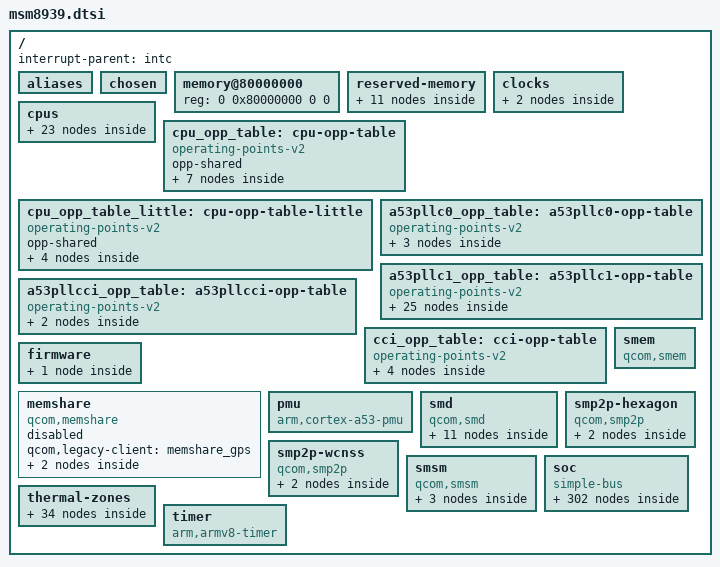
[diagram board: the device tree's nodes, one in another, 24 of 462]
// SPDX-License-Identifier: GPL-2.0-only
/*
 * Copyright (c) 2013-2015, The Linux Foundation. All rights reserved.
 */

#include <dt-bindings/arm/coresight-cti-dt.h>
#include <dt-bindings/clock/qcom,gcc-msm8939.h>
#include <dt-bindings/clock/qcom,rpmcc.h>
#include <dt-bindings/interconnect/qcom,msm8939.h>
#include <dt-bindings/interrupt-controller/arm-gic.h>
#include <dt-bindings/power/qcom-rpmpd.h>
#include <dt-bindings/reset/qcom,gcc-msm8939.h>
#include <dt-bindings/soc/qcom,apr.h>
#include <dt-bindings/soc/qcom,memshare.h>
#include <dt-bindings/thermal/thermal.h>

/ {
	interrupt-parent = <&intc>;

	#address-cells = <2>;
	#size-cells = <2>;

	aliases {
		sdhc1 = &sdhc_1; /* SDC1 eMMC slot */
		sdhc2 = &sdhc_2; /* SDC2 SD card slot */
	};

	chosen { };

	memory@80000000 {
		device_type = "memory";
		/* We expect the bootloader to fill in the reg */
		reg = <0 0x80000000 0 0>;
	};

	reserved-memory {
		#address-cells = <2>;
		#size-cells = <2>;
		ranges;

		tz-apps@86000000 {
			reg = <0x0 0x86000000 0x0 0x300000>;
			no-map;
		};

		smem_mem: smem_region@86300000 {
			reg = <0x0 0x86300000 0x0 0x100000>;
			no-map;
		};

		hypervisor@86400000 {
			reg = <0x0 0x86400000 0x0 0x100000>;
			no-map;
		};

		tz@86500000 {
			reg = <0x0 0x86500000 0x0 0x180000>;
			no-map;
		};

		reserved@86680000 {
			reg = <0x0 0x86680000 0x0 0x1000>;
			no-map;
		};

		rmtfs@86681000 {
			compatible = "qcom,rmtfs-mem";
			reg = <0x0 0x86681000 0x0 0x15f000>;
			no-map;

			qcom,client-id = <1>;
		};

		rfsa@867e0000 {
			reg = <0x0 0x867e0000 0x0 0x20000>;
			no-map;
		};

		mpss_mem: mpss@86800000 {
			reg = <0x0 0x86800000 0x0 0x5600000>;
			no-map;
		};

		wcnss_mem: wcnss@8be00000 {
			reg = <0x0 0x8be00000 0x0 0x600000>;
			no-map;
		};

		mba_mem: mba@8ea00000 {
			reg = <0x0 0x8ea00000 0x0 0x100000>;
			no-map;
		};

		venus_mem: venus@90000000 {
			reg = <0x0 0x90000000 0x0 0x600000>;
			no-map;
		};
	};

	clocks {
		xo_board: xo-board {
			compatible = "fixed-clock";
			#clock-cells = <0>;
			clock-frequency = <19200000>;
		};

		sleep_clk: sleep-clk {
			compatible = "fixed-clock";
			#clock-cells = <0>;
			clock-frequency = <32768>;
		};
	};

	cpus {
		#address-cells = <1>;
		#size-cells = <0>;

		cpu-map {
			cluster0 {	/* little */
				core0 {
					cpu = <&CPU4>;
				};
				core1 {
					cpu = <&CPU5>;
				};
				core2 {
					cpu = <&CPU6>;
				};
				core3 {
					cpu = <&CPU7>;
				};
			};

			cluster1 {	/* BIG */
				core0 {
					cpu = <&CPU0>;
				};
				core1 {
					cpu = <&CPU1>;
				};
				core2 {
					cpu = <&CPU2>;
				};
				core3 {
					cpu = <&CPU3>;
				};
			};
		};

		CPU0: cpu@100 {
			device_type = "cpu";
			compatible = "arm,cortex-a53";
			reg = <0x100>;
			next-level-cache = <&L2_1>;
			enable-method = "spin-table";
			clocks = <&apcs_mbox>;
			//operating-points-v2 = <&cpu_opp_table>;
			#cooling-cells = <2>;
			qcom,acc = <&cpu0_acc>;
			qcom,saw = <&cpu0_saw>;
			cpu-idle-states = <&CPU_SPC>;
		};

		CPU1: cpu@101 {
			device_type = "cpu";
			compatible = "arm,cortex-a53";
			reg = <0x101>;
			next-level-cache = <&L2_1>;
			enable-method = "spin-table";
			clocks = <&apcs_mbox>;
			//operating-points-v2 = <&cpu_opp_table>;
			#cooling-cells = <2>;
			qcom,acc = <&cpu1_acc>;
			qcom,saw = <&cpu1_saw>;
		};

		CPU2: cpu@102 {
			device_type = "cpu";
			compatible = "arm,cortex-a53";
			reg = <0x102>;
			next-level-cache = <&L2_1>;
			enable-method = "spin-table";
			clocks = <&apcs_mbox>;
			//operating-points-v2 = <&cpu_opp_table>;
			#cooling-cells = <2>;
			qcom,acc = <&cpu2_acc>;
			qcom,saw = <&cpu2_saw>;
		};

		CPU3: cpu@103 {
			device_type = "cpu";
			compatible = "arm,cortex-a53";
			reg = <0x103>;
			next-level-cache = <&L2_1>;
			enable-method = "spin-table";
			clocks = <&apcs_mbox>;
			//operating-points-v2 = <&cpu_opp_table>;
			#cooling-cells = <2>;
			qcom,acc = <&cpu3_acc>;
			qcom,saw = <&cpu3_saw>;
		};

		CPU4: cpu@0 {
			device_type = "cpu";
			compatible = "arm,cortex-a53";
			reg = <0x0>;
			next-level-cache = <&L2_0>;
			enable-method = "spin-table";
			clocks = <&apcs0>;
			//operating-points-v2 = <&cpu_opp_table_little>;
			#cooling-cells = <2>;
			qcom,acc = <&cpu4_acc>;
			qcom,saw = <&cpu4_saw>;
		};

		CPU5: cpu@1 {
			device_type = "cpu";
			compatible = "arm,cortex-a53";
			reg = <0x1>;
			next-level-cache = <&L2_0>;
			enable-method = "spin-table";
			clocks = <&apcs0>;
			//operating-points-v2 = <&cpu_opp_table_little>;
			#cooling-cells = <2>;
			qcom,acc = <&cpu5_acc>;
			qcom,saw = <&cpu5_saw>;
		};

		CPU6: cpu@2 {
			device_type = "cpu";
			compatible = "arm,cortex-a53";
			reg = <0x2>;
			next-level-cache = <&L2_0>;
			enable-method = "spin-table";
			clocks = <&apcs0>;
			//operating-points-v2 = <&cpu_opp_table_little>;
			#cooling-cells = <2>;
			qcom,acc = <&cpu6_acc>;
			qcom,saw = <&cpu6_saw>;
		};

		CPU7: cpu@3 {
			device_type = "cpu";
			compatible = "arm,cortex-a53";
			reg = <0x3>;
			next-level-cache = <&L2_0>;
			enable-method = "spin-table";
			clocks = <&apcs0>;
			//operating-points-v2 = <&cpu_opp_table_little>;
			#cooling-cells = <2>;
			qcom,acc = <&cpu7_acc>;
			qcom,saw = <&cpu7_saw>;
		};

		L2_0: l2-cache { /* little cluster */
			compatible = "cache";
			cache-level = <2>;
		};

		L2_1: l2-cache-1 { /* BIG cluster */
			compatible = "cache";
			cache-level = <2>;
		};

		idle-states {
			CPU_SPC: spc {
				compatible = "arm,idle-state";
				arm,psci-suspend-param = <0x40000002>;
				entry-latency-us = <130>;
				exit-latency-us = <150>;
				min-residency-us = <2000>;
				local-timer-stop;
			};
		};
	};

	cpu_opp_table: cpu-opp-table {
		compatible = "operating-points-v2";
		opp-shared;

		opp-200000000 {
			opp-hz = /bits/ 64 <200000000>;
		};
		opp-345600000 {
			opp-hz = /bits/ 64 <345600000>;
		};
		opp-400000000 {
			opp-hz = /bits/ 64 <400000000>;
		};
		opp-533330000 {
			opp-hz = /bits/ 64 <533330000>;
		};
		opp-800000000 {
			opp-hz = /bits/ 64 <800000000>;
		};
		opp-960000000 {
			opp-hz = /bits/ 64 <960000000>;
		};
		opp-1113600000 {
			opp-hz = /bits/ 64 <1113600000>;
		};
		/*
		opp-1344000000 {
			opp-hz = /bits/ 64 <1344000000>;
		};
		opp-1459200000 {
			opp-hz = /bits/ 64 <1459200000>;
		};
		opp-1497600000 {
			opp-hz = /bits/ 64 <1497600000>;
		};
		opp-1651200000 {
			opp-hz = /bits/ 64 <1651200000>;
		};
		*/
	};

	cpu_opp_table_little: cpu-opp-table-little {
		compatible = "operating-points-v2";
		opp-shared;

		opp-200000000 {
			opp-hz = /bits/ 64 <200000000>;
		};
		opp-249600000 {
			opp-hz = /bits/ 64 <249600000>;
		};
		opp-499200000 {
			opp-hz = /bits/ 64 <499200000>;
		};
		opp-800000000 {
			opp-hz = /bits/ 64 <800000000>;
		};
		/*
		opp-998400000 {
			opp-hz = /bits/ 64 <998400000>;
		};
		opp-1113600000 {
			opp-hz = /bits/ 64 <1113600000>;
		};
		*/
	};

	a53pllc0_opp_table: a53pllc0-opp-table {
		compatible = "operating-points-v2";

		opp-998400000 {
			opp-hz = /bits/ 64 <998400000>;
		};

		opp-1113600000 {
			opp-hz = /bits/ 64 <1113600000>;
		};

		opp-1209600000 {
			opp-hz = /bits/ 64 <1209600000>;
		};
	};

	a53pllc1_opp_table: a53pllc1-opp-table {
		compatible = "operating-points-v2";

		opp-652800000 {
			opp-hz = /bits/ 64 <652800000>;
		};

		opp-691200000 {
			opp-hz = /bits/ 64 <691200000>;
		};

		opp-729600000 {
			opp-hz = /bits/ 64 <729600000>;
		};

		opp-806400000 {
			opp-hz = /bits/ 64 <806400000>;
		};

		opp-844800000 {
			opp-hz = /bits/ 64 <844800000>;
		};

		opp-883200000 {
			opp-hz = /bits/ 64 <883200000>;
		};

		opp-960000000 {
			opp-hz = /bits/ 64 <960000000>;
		};

		opp-998400000 {
			opp-hz = /bits/ 64 <998400000>;
		};

		opp-1036800000 {
			opp-hz = /bits/ 64 <1036800000>;
		};

		opp-1113600000 {
			opp-hz = /bits/ 64 <1113600000>;
		};

		opp-1190400000 {
			opp-hz = /bits/ 64 <1190400000>;
		};

		opp-1209600000 {
			opp-hz = /bits/ 64 <1209600000>;
		};

		opp-1267200000 {
			opp-hz = /bits/ 64 <1267200000>;
		};

		opp-1344000000 {
			opp-hz = /bits/ 64 <1344000000>;
		};

		opp-1363200000 {
			opp-hz = /bits/ 64 <1363200000>;
		};

		opp-1420800000 {
			opp-hz = /bits/ 64 <1420800000>;
		};

		opp-1459200000 {
			opp-hz = /bits/ 64 <1459200000>;
		};

		opp-1497600000 {
			opp-hz = /bits/ 64 <1497600000>;
		};

		opp-1536000000 {
			opp-hz = /bits/ 64 <1536000000>;
		};

		opp-1574400000 {
			opp-hz = /bits/ 64 <1574400000>;
		};

		opp-1612800000 {
			opp-hz = /bits/ 64 <1612800000>;
		};

		opp-1632000000 {
			opp-hz = /bits/ 64 <1632000000>;
		};

		opp-1651200000 {
			opp-hz = /bits/ 64 <1651200000>;
		};

		opp-1689600000 {
			opp-hz = /bits/ 64 <1689600000>;
		};

		opp-1708800000 {
			opp-hz = /bits/ 64 <1708800000>;
		};
	};

	a53pllcci_opp_table: a53pllcci-opp-table {
		compatible = "operating-points-v2";

		opp-403200000 {
			opp-hz = /bits/ 64 <403200000>;
		};

		opp-595200000 {
			opp-hz = /bits/ 64 <595200000>;
		};
	};

	cci_opp_table: cci-opp-table {
		compatible = "operating-points-v2";

		opp-200000000 {
			opp-hz = /bits/ 64 <200000000>;
		};

		opp-297600000 {
			opp-hz = /bits/ 64 <297600000>;
		};

		opp-400000000 {
			opp-hz = /bits/ 64 <400000000>;
		};

		opp-595200000 {
			opp-hz = /bits/ 64 <595200000>;
		};

		/* Frequency mapping between cci and cluster/cpu */
		/*
		cpu-to-dev-map-0 =
			<  200000  200000 >,
			<  345600  200000 >,
			<  400000  200000 >,
			<  533330  297600 >,
			<  800000  297600 >,
			<  960000  297600 >,
			< 1113600  297000 >,
			< 1344000  595200 >,
			< 1459200  595200 >,
			< 1497600  595200 >,
			< 1651200  595200 >;
		cpu-to-dev-map-4 =
			<  200000 200000 >,
			<  249600 200000 >,
			<  499200 297600 >,
			<  800000 297600 >,
			<  998400 595200 >,
			< 1113600 595200 >;
		*/
	};

	firmware {
		scm: scm {
			compatible = "qcom,scm-msm8916", "qcom,scm";
			clocks = <&gcc GCC_CRYPTO_CLK>,
				 <&gcc GCC_CRYPTO_AXI_CLK>,
				 <&gcc GCC_CRYPTO_AHB_CLK>;
			clock-names = "core", "bus", "iface";
			#reset-cells = <1>;

			qcom,dload-mode = <&tcsr 0x6100>;
		};
	};

	memshare: memshare {
		compatible = "qcom,memshare";
		qcom,legacy-client = <&memshare_gps>;

		status = "disabled";

		#address-cells = <1>;
		#size-cells = <0>;

		mpss@0 {
			reg = <MEMSHARE_PROC_MPSS_V01>;
			qcom,qrtr-node = <0>;

			#address-cells = <1>;
			#size-cells = <0>;

			memshare_gps: gps@0 {
				reg = <0>;
			};
		};
	};

	pmu {
		compatible = "arm,cortex-a53-pmu";
		interrupts = <GIC_PPI 7 (GIC_CPU_MASK_SIMPLE(4) | IRQ_TYPE_LEVEL_HIGH)>;
	};

	smd {
		compatible = "qcom,smd";

		rpm {
			interrupts = <GIC_SPI 168 IRQ_TYPE_EDGE_RISING>;
			qcom,ipc = <&apcs 8 0>;
			qcom,smd-edge = <15>;

			rpm_requests: rpm-requests {
				compatible = "qcom,rpm-msm8936";
				qcom,smd-channels = "rpm_requests";

				rpmcc: clock-controller {
					compatible = "qcom,rpmcc-msm8936";
					#clock-cells = <1>;
				};

				rpmpd: power-controller {
					compatible = "qcom,msm8939-rpmpd";
					#power-domain-cells = <1>;
					operating-points-v2 = <&rpmpd_opp_table>;

					rpmpd_opp_table: opp-table {
						compatible = "operating-points-v2";

						rpmpd_opp_ret: opp1 {
							opp-level = <1>;
						};
						rpmpd_opp_svs_krait: opp2 {
							opp-level = <2>;
						};
						rpmpd_opp_svs_soc: opp3 {
							opp-level = <3>;
						};
						rpmpd_opp_nom: opp4 {
							opp-level = <4>;
						};
						rpmpd_opp_turbo: opp5 {
							opp-level = <5>;
						};
						rpmpd_opp_super_turbo: opp6 {
							opp-level = <6>;
						};
					};
				};
			};
		};
	};

	smem {
		compatible = "qcom,smem";

		memory-region = <&smem_mem>;
		qcom,rpm-msg-ram = <&rpm_msg_ram>;

		hwlocks = <&tcsr_mutex 3>;
	};

	smp2p-hexagon {
		compatible = "qcom,smp2p";
		qcom,smem = <435>, <428>;

		interrupts = <GIC_SPI 27 IRQ_TYPE_EDGE_RISING>;

		mboxes = <&apcs_mbox 14>;

		qcom,local-pid = <0>;
		qcom,remote-pid = <1>;

		hexagon_smp2p_out: master-kernel {
			qcom,entry-name = "master-kernel";

			#qcom,smem-state-cells = <1>;
		};

		hexagon_smp2p_in: slave-kernel {
			qcom,entry-name = "slave-kernel";

			interrupt-controller;
			#interrupt-cells = <2>;
		};
	};

	smp2p-wcnss {
		compatible = "qcom,smp2p";
		qcom,smem = <451>, <431>;

		interrupts = <GIC_SPI 143 IRQ_TYPE_EDGE_RISING>;

		mboxes = <&apcs_mbox 18>;

		qcom,local-pid = <0>;
		qcom,remote-pid = <4>;

		wcnss_smp2p_out: master-kernel {
			qcom,entry-name = "master-kernel";

			#qcom,smem-state-cells = <1>;
		};

		wcnss_smp2p_in: slave-kernel {
			qcom,entry-name = "slave-kernel";

			interrupt-controller;
			#interrupt-cells = <2>;
		};
	};

	smsm {
		compatible = "qcom,smsm";

		#address-cells = <1>;
		#size-cells = <0>;

		qcom,ipc-1 = <&apcs 8 13>;
		qcom,ipc-3 = <&apcs 8 19>;

		apps_smsm: apps@0 {
			reg = <0>;

			#qcom,smem-state-cells = <1>;
		};

		hexagon_smsm: hexagon@1 {
			reg = <1>;
			interrupts = <GIC_SPI 26 IRQ_TYPE_EDGE_RISING>;

			interrupt-controller;
			#interrupt-cells = <2>;
		};

		wcnss_smsm: wcnss@6 {
			reg = <6>;
			interrupts = <GIC_SPI 144 IRQ_TYPE_EDGE_RISING>;

			interrupt-controller;
			#interrupt-cells = <2>;
		};
	};

	soc: soc {
		#address-cells = <1>;
		#size-cells = <1>;
		ranges = <0 0 0 0xffffffff>;
		compatible = "simple-bus";

		rng@22000 {
			compatible = "qcom,prng";
			reg = <0x00022000 0x200>;
			clocks = <&gcc GCC_PRNG_AHB_CLK>;
			clock-names = "core";
		};

		restart@4ab000 {
			compatible = "qcom,pshold";
			reg = <0x004ab000 0x4>;
		};

		qfprom: qfprom@5c000 {
			compatible = "qcom,qfprom";
			reg = <0x0005c000 0x1000>;
			#address-cells = <1>;
			#size-cells = <1>;
			tsens_caldata: caldata@d0 {
				reg = <0xd0 0x8>;
			};
			tsens_calsel: calsel@ec {
				reg = <0xec 0x4>;
			};
		};

		rpm_msg_ram: memory@60000 {
			compatible = "qcom,rpm-msg-ram";
			reg = <0x00060000 0x8000>;
		};

		bimc: interconnect@400000 {
			compatible = "qcom,msm8939-bimc";
			reg = <0x00400000 0x62000>;
			#interconnect-cells = <1>;
			clock-names = "bus", "bus_a";
			clocks = <&rpmcc RPM_SMD_BIMC_CLK>,
				 <&rpmcc RPM_SMD_BIMC_A_CLK>;
		};

		tsens: thermal-sensor@4a9000 {
			compatible = "qcom,msm8939-tsens";
			reg = <0x004a9000 0x1000>, /* TM */
			      <0x004a8000 0x1000>; /* SROT */
			nvmem-cells = <&tsens_caldata>, <&tsens_calsel>;
			nvmem-cell-names = "calib", "calib_sel";
			#qcom,sensors = <10>;
			interrupts = <GIC_SPI 184 IRQ_TYPE_LEVEL_HIGH>;
			interrupt-names = "uplow";
			#thermal-sensor-cells = <1>;
		};

		pcnoc: interconnect@500000 {
			compatible = "qcom,msm8939-pcnoc";
			reg = <0x00500000 0x11000>;
			#interconnect-cells = <1>;
			clock-names = "bus", "bus_a";
			clocks = <&rpmcc RPM_SMD_PCNOC_CLK>,
				 <&rpmcc RPM_SMD_PCNOC_A_CLK>;
		};

		snoc: interconnect@580000 {
			compatible = "qcom,msm8939-snoc";
			reg = <0x00580000 0x14080>;
			clock-names = "bus", "bus_a";
			clocks = <&rpmcc RPM_SMD_SNOC_CLK>,
				 <&rpmcc RPM_SMD_SNOC_A_CLK>;
			#interconnect-cells = <1>;
			status = "okay";

			snoc_mm: interconnect@580000 {
				compatible = "qcom,msm8939-snoc-mm";
				clock-names = "bus", "bus_a";
				clocks = <&rpmcc RPM_SMD_SYSMMNOC_CLK>,
					 <&rpmcc RPM_SMD_SYSMMNOC_A_CLK>;
				#interconnect-cells = <1>;
				status = "okay";
			};

		};

		stm: stm@802000 {
			compatible = "arm,coresight-stm", "arm,primecell";
			reg = <0x00802000 0x1000>,
			      <0x09280000 0x180000>;
			reg-names = "stm-base", "stm-stimulus-base";

			clocks = <&rpmcc RPM_QDSS_CLK>, <&rpmcc RPM_QDSS_A_CLK>;
			clock-names = "apb_pclk", "atclk";

			status = "disabled";

			out-ports {
				port {
					stm_out: endpoint {
						remote-endpoint = <&funnel0_in7>;
					};
				};
			};
		};

		/* System CTIs */
		/* CTI 0 - TMC connections */
		cti0: cti@810000 {
			compatible = "arm,coresight-cti", "arm,primecell";
			reg = <0x00810000 0x1000>;

			clocks = <&rpmcc RPM_QDSS_CLK>;
			clock-names = "apb_pclk";

			status = "disabled";
		};

		/* CTI 1 - TPIU connections */
		cti1: cti@811000 {
			compatible = "arm,coresight-cti", "arm,primecell";
			reg = <0x00811000 0x1000>;

			clocks = <&rpmcc RPM_QDSS_CLK>;
			clock-names = "apb_pclk";

			status = "disabled";
		};

		/* CTIs 2-11 - no information - not instantiated */

		tpiu: tpiu@820000 {
			compatible = "arm,coresight-tpiu", "arm,primecell";
			reg = <0x00820000 0x1000>;

			clocks = <&rpmcc RPM_QDSS_CLK>, <&rpmcc RPM_QDSS_A_CLK>;
			clock-names = "apb_pclk", "atclk";

			status = "disabled";

			in-ports {
				port {
					tpiu_in: endpoint {
						remote-endpoint = <&replicator_out1>;
					};
				};
			};
		};

		funnel0: funnel@821000 {
			compatible = "arm,coresight-dynamic-funnel", "arm,primecell";
			reg = <0x00821000 0x1000>;

			clocks = <&rpmcc RPM_QDSS_CLK>, <&rpmcc RPM_QDSS_A_CLK>;
			clock-names = "apb_pclk", "atclk";

			status = "disabled";

			in-ports {
				#address-cells = <1>;
				#size-cells = <0>;

				/*
				 * Not described input ports:
				 * 0 - connected to Resource and Power Manger CPU ETM
				 * 1 - not-connected
				 * 2 - connected to Modem CPU ETM
				 * 3 - not-connected
				 * 5 - not-connected
				 * 6 - connected trought funnel to Wireless CPU ETM
				 * 7 - connected to STM component
				 */

				port@4 {
					reg = <4>;
					funnel0_in4: endpoint {
						remote-endpoint = <&funnel1_out>;
					};
				};

				port@7 {
					reg = <7>;
					funnel0_in7: endpoint {
						remote-endpoint = <&stm_out>;
					};
				};
			};

			out-ports {
				port {
					funnel0_out: endpoint {
						remote-endpoint = <&etf_in>;
					};
				};
			};
		};

		replicator: replicator@824000 {
			compatible = "arm,coresight-dynamic-replicator", "arm,primecell";
			reg = <0x00824000 0x1000>;

			clocks = <&rpmcc RPM_QDSS_CLK>, <&rpmcc RPM_QDSS_A_CLK>;
			clock-names = "apb_pclk", "atclk";

			status = "disabled";

			out-ports {
				#address-cells = <1>;
				#size-cells = <0>;

				port@0 {
					reg = <0>;
					replicator_out0: endpoint {
						remote-endpoint = <&etr_in>;
					};
				};
				port@1 {
					reg = <1>;
					replicator_out1: endpoint {
						remote-endpoint = <&tpiu_in>;
					};
				};
			};

			in-ports {
				port {
					replicator_in: endpoint {
						remote-endpoint = <&etf_out>;
					};
				};
			};
		};

		etf: etf@825000 {
			compatible = "arm,coresight-tmc", "arm,primecell";
			reg = <0x00825000 0x1000>;

			clocks = <&rpmcc RPM_QDSS_CLK>, <&rpmcc RPM_QDSS_A_CLK>;
			clock-names = "apb_pclk", "atclk";

			status = "disabled";

			in-ports {
				port {
					etf_in: endpoint {
						remote-endpoint = <&funnel0_out>;
					};
				};
			};

			out-ports {
				port {
					etf_out: endpoint {
						remote-endpoint = <&replicator_in>;
					};
				};
			};
		};

		etr: etr@826000 {
			compatible = "arm,coresight-tmc", "arm,primecell";
			reg = <0x00826000 0x1000>;

			clocks = <&rpmcc RPM_QDSS_CLK>, <&rpmcc RPM_QDSS_A_CLK>;
			clock-names = "apb_pclk", "atclk";

			status = "disabled";

			in-ports {
				port {
					etr_in: endpoint {
						remote-endpoint = <&replicator_out0>;
					};
				};
			};
		};

		funnel1: funnel@841000 {	/* APSS funnel only 4 inputs are used */
			compatible = "arm,coresight-dynamic-funnel", "arm,primecell";
			reg = <0x00841000 0x1000>;

			clocks = <&rpmcc RPM_QDSS_CLK>, <&rpmcc RPM_QDSS_A_CLK>;
			clock-names = "apb_pclk", "atclk";

			status = "disabled";

			in-ports {
				#address-cells = <1>;
				#size-cells = <0>;

				port@0 {
					reg = <0>;
					funnel1_in0: endpoint {
						remote-endpoint = <&etm0_out>;
					};
				};
				port@1 {
					reg = <1>;
					funnel1_in1: endpoint {
						remote-endpoint = <&etm1_out>;
					};
				};
				port@2 {
					reg = <2>;
					funnel1_in2: endpoint {
						remote-endpoint = <&etm2_out>;
					};
				};
				port@3 {
					reg = <3>;
					funnel1_in3: endpoint {
						remote-endpoint = <&etm3_out>;
					};
				};
			};

			out-ports {
				port {
					funnel1_out: endpoint {
						remote-endpoint = <&funnel0_in4>;
					};
				};
			};
		};

		debug0: debug@850000 {
			compatible = "arm,coresight-cpu-debug", "arm,primecell";
			reg = <0x00850000 0x1000>;
			clocks = <&rpmcc RPM_QDSS_CLK>;
			clock-names = "apb_pclk";
			cpu = <&CPU0>;
			status = "disabled";
		};

		debug1: debug@852000 {
			compatible = "arm,coresight-cpu-debug", "arm,primecell";
			reg = <0x00852000 0x1000>;
			clocks = <&rpmcc RPM_QDSS_CLK>;
			clock-names = "apb_pclk";
			cpu = <&CPU1>;
			status = "disabled";
		};

		debug2: debug@854000 {
			compatible = "arm,coresight-cpu-debug", "arm,primecell";
			reg = <0x00854000 0x1000>;
			clocks = <&rpmcc RPM_QDSS_CLK>;
			clock-names = "apb_pclk";
			cpu = <&CPU2>;
			status = "disabled";
		};

		debug3: debug@856000 {
			compatible = "arm,coresight-cpu-debug", "arm,primecell";
			reg = <0x00856000 0x1000>;
			clocks = <&rpmcc RPM_QDSS_CLK>;
			clock-names = "apb_pclk";
			cpu = <&CPU3>;
			status = "disabled";
		};

		/* Core CTIs; CTIs 12-15 */
		/* CTI - CPU-0 */
		cti12: cti@858000 {
			compatible = "arm,coresight-cti-v8-arch", "arm,coresight-cti",
				     "arm,primecell";
			reg = <0x00858000 0x1000>;

			clocks = <&rpmcc RPM_QDSS_CLK>;
			clock-names = "apb_pclk";

			cpu = <&CPU0>;
			arm,cs-dev-assoc = <&etm0>;

			status = "disabled";
		};

		/* CTI - CPU-1 */
		cti13: cti@859000 {
			compatible = "arm,coresight-cti-v8-arch", "arm,coresight-cti",
				     "arm,primecell";
			reg = <0x00859000 0x1000>;

			clocks = <&rpmcc RPM_QDSS_CLK>;
			clock-names = "apb_pclk";

			cpu = <&CPU1>;
			arm,cs-dev-assoc = <&etm1>;

			status = "disabled";
		};

		/* CTI - CPU-2 */
		cti14: cti@85a000 {
			compatible = "arm,coresight-cti-v8-arch", "arm,coresight-cti",
				     "arm,primecell";
			reg = <0x0085a000 0x1000>;

			clocks = <&rpmcc RPM_QDSS_CLK>;
			clock-names = "apb_pclk";

			cpu = <&CPU2>;
			arm,cs-dev-assoc = <&etm2>;

			status = "disabled";
		};

		/* CTI - CPU-3 */
		cti15: cti@85b000 {
			compatible = "arm,coresight-cti-v8-arch", "arm,coresight-cti",
				     "arm,primecell";
			reg = <0x0085b000 0x1000>;

			clocks = <&rpmcc RPM_QDSS_CLK>;
			clock-names = "apb_pclk";

			cpu = <&CPU3>;
			arm,cs-dev-assoc = <&etm3>;

			status = "disabled";
		};

		etm0: etm@85c000 {
			compatible = "arm,coresight-etm4x", "arm,primecell";
			reg = <0x0085c000 0x1000>;

			clocks = <&rpmcc RPM_QDSS_CLK>, <&rpmcc RPM_QDSS_A_CLK>;
			clock-names = "apb_pclk", "atclk";
			arm,coresight-loses-context-with-cpu;

			cpu = <&CPU0>;

			status = "disabled";

			out-ports {
				port {
					etm0_out: endpoint {
						remote-endpoint = <&funnel1_in0>;
					};
				};
			};
		};

		etm1: etm@85d000 {
			compatible = "arm,coresight-etm4x", "arm,primecell";
			reg = <0x0085d000 0x1000>;

			clocks = <&rpmcc RPM_QDSS_CLK>, <&rpmcc RPM_QDSS_A_CLK>;
			clock-names = "apb_pclk", "atclk";
			arm,coresight-loses-context-with-cpu;

			cpu = <&CPU1>;

			status = "disabled";

			out-ports {
				port {
					etm1_out: endpoint {
						remote-endpoint = <&funnel1_in1>;
					};
				};
			};
		};

		etm2: etm@85e000 {
			compatible = "arm,coresight-etm4x", "arm,primecell";
			reg = <0x0085e000 0x1000>;

			clocks = <&rpmcc RPM_QDSS_CLK>, <&rpmcc RPM_QDSS_A_CLK>;
			clock-names = "apb_pclk", "atclk";
			arm,coresight-loses-context-with-cpu;

			cpu = <&CPU2>;

			status = "disabled";

			out-ports {
				port {
					etm2_out: endpoint {
						remote-endpoint = <&funnel1_in2>;
					};
				};
			};
		};

		etm3: etm@85f000 {
			compatible = "arm,coresight-etm4x", "arm,primecell";
			reg = <0x0085f000 0x1000>;

			clocks = <&rpmcc RPM_QDSS_CLK>, <&rpmcc RPM_QDSS_A_CLK>;
			clock-names = "apb_pclk", "atclk";
			arm,coresight-loses-context-with-cpu;

			cpu = <&CPU3>;

			status = "disabled";

			out-ports {
				port {
					etm3_out: endpoint {
						remote-endpoint = <&funnel1_in3>;
					};
				};
			};
		};

		msmgpio: pinctrl@1000000 {
			compatible = "qcom,msm8916-pinctrl";
			reg = <0x01000000 0x300000>;
			interrupts = <GIC_SPI 208 IRQ_TYPE_LEVEL_HIGH>;
			gpio-controller;
			gpio-ranges = <&msmgpio 0 0 122>;
			#gpio-cells = <2>;
			interrupt-controller;
			#interrupt-cells = <2>;

			blsp1_uart1_default: blsp1-uart1-default {
				pins = "gpio0", "gpio1", "gpio2", "gpio3";
				function = "blsp_uart1";

				drive-strength = <16>;
				bias-disable;
			};

			blsp1_uart1_sleep: blsp1-uart1-sleep {
				pins = "gpio0", "gpio1", "gpio2", "gpio3";
				function = "gpio";

				drive-strength = <2>;
				bias-pull-down;
			};

			blsp1_uart2_default: blsp1-uart2-default {
				pins = "gpio4", "gpio5";
				function = "blsp_uart2";

				drive-strength = <16>;
				bias-disable;
			};

			blsp1_uart2_sleep: blsp1-uart2-sleep {
				pins = "gpio4", "gpio5";
				function = "gpio";

				drive-strength = <2>;
				bias-pull-down;
			};

			camera_front_default: camera-front-default {
				pwdn {
					pins = "gpio33";
					function = "gpio";

					drive-strength = <16>;
					bias-disable;
				};
				rst {
					pins = "gpio28";
					function = "gpio";

					drive-strength = <16>;
					bias-disable;
				};
				mclk1 {
					pins = "gpio27";
					function = "cam_mclk1";

					drive-strength = <16>;
					bias-disable;
				};
			};

			camera_rear_default: camera-rear-default {
				pwdn {
					pins = "gpio34";
					function = "gpio";

					drive-strength = <16>;
					bias-disable;
				};
				rst {
					pins = "gpio35";
					function = "gpio";

					drive-strength = <16>;
					bias-disable;
				};
				mclk0 {
					pins = "gpio26";
					function = "cam_mclk0";

					drive-strength = <16>;
					bias-disable;
				};
			};

			cci0_default: cci0-default {
				pins = "gpio29", "gpio30";
				function = "cci_i2c";

				drive-strength = <16>;
				bias-disable;
			};

			cdc-pdm-lines {
				cdc_pdm_lines_act: pdm-lines-on {
					pins = "gpio63", "gpio64", "gpio65", "gpio66",
					       "gpio67", "gpio68";
					function = "cdc_pdm0";

					drive-strength = <8>;
					bias-disable;
				};
				cdc_pdm_lines_sus: pdm-lines-off {
					pins = "gpio63", "gpio64", "gpio65", "gpio66",
					       "gpio67", "gpio68";
					function = "cdc_pdm0";

					drive-strength = <2>;
					bias-pull-down;
				};
			};

			cdc-dmic-lines {
				cdc_dmic_lines_act: dmic-lines-on {
					clk {
						pins = "gpio0";
						function = "dmic0_clk";

						drive-strength = <8>;
					};
					data {
						pins = "gpio1";
						function = "dmic0_data";

						drive-strength = <8>;
					};
				};
				cdc_dmic_lines_sus: dmic-lines-off {
					clk {
						pins = "gpio0";
						function = "dmic0_clk";

						drive-strength = <2>;
						bias-disable;
					};
					data {
						pins = "gpio1";
						function = "dmic0_data";

						drive-strength = <2>;
						bias-disable;
					};
				};
			};

			ext-mclk-tlmm-lines {
				ext_mclk_tlmm_lines_act: mclk-lines-on {
					pins = "gpio116";
					function = "pri_mi2s";

					drive-strength = <8>;
					bias-disable;
				};
				ext_mclk_tlmm_lines_sus: mclk-lines-off {
					pins = "gpio116";
					function = "pri_mi2s";

					drive-strength = <2>;
					bias-disable;
				};
			};

			ext-pri-tlmm-lines {
				ext_pri_tlmm_lines_act: ext-pa-on {
					pins = "gpio113", "gpio114", "gpio115", "gpio116";
					function = "pri_mi2s";

					drive-strength = <8>;
					bias-disable;
				};
				ext_pri_tlmm_lines_sus: ext-pa-off {
					pins = "gpio113", "gpio114", "gpio115", "gpio116";
					function = "pri_mi2s";

					drive-strength = <2>;
					bias-disable;
				};
			};

			ext-pri-ws-line {
				ext_pri_ws_act: ext-pa-on {
					pins = "gpio110";
					function = "pri_mi2s_ws";

					drive-strength = <8>;
					bias-disable;
				};
				ext_pri_ws_sus: ext-pa-off {
					pins = "gpio110";
					function = "pri_mi2s_ws";

					drive-strength = <2>;
					bias-disable;
				};
			};

			/* secondary Mi2S */
			ext-sec-tlmm-lines {
				ext_sec_tlmm_lines_act: tlmm-lines-on {
					pins = "gpio112", "gpio117", "gpio118", "gpio119";
					function = "sec_mi2s";

					drive-strength = <8>;
					bias-disable;
				};
				ext_sec_tlmm_lines_sus: tlmm-lines-off {
					pins = "gpio112", "gpio117", "gpio118", "gpio119";
					function = "sec_mi2s";

					drive-strength = <2>;
					bias-disable;
				};
			};

			i2c1_default: i2c1-default {
				pins = "gpio2", "gpio3";
				function = "blsp_i2c1";

				drive-strength = <2>;
				bias-disable;
			};

			i2c1_sleep: i2c1-sleep {
				pins = "gpio2", "gpio3";
				function = "gpio";

				drive-strength = <2>;
				bias-disable;
			};

			i2c2_default: i2c2-default {
				pins = "gpio6", "gpio7";
				function = "blsp_i2c2";

				drive-strength = <2>;
				bias-disable;
			};

			i2c2_sleep: i2c2-sleep {
				pins = "gpio6", "gpio7";
				function = "gpio";

				drive-strength = <2>;
				bias-disable;
			};

			i2c3_default: i2c3-default {
				pins = "gpio10", "gpio11";
				function = "blsp_i2c3";

				drive-strength = <2>;
				bias-disable;
			};

			i2c3_sleep: i2c3-sleep {
				pins = "gpio10", "gpio11";
				function = "gpio";

				drive-strength = <2>;
				bias-disable;
			};

			i2c4_default: i2c4-default {
				pins = "gpio14", "gpio15";
				function = "blsp_i2c4";

				drive-strength = <2>;
				bias-disable;
			};

			i2c4_sleep: i2c4-sleep {
				pins = "gpio14", "gpio15";
				function = "gpio";

				drive-strength = <2>;
				bias-disable;
			};

			i2c5_default: i2c5-default {
				pins = "gpio18", "gpio19";
				function = "blsp_i2c5";

				drive-strength = <2>;
				bias-disable;
			};

			i2c5_sleep: i2c5-sleep {
				pins = "gpio18", "gpio19";
				function = "gpio";

				drive-strength = <2>;
				bias-disable;
			};

			i2c6_default: i2c6-default {
				pins = "gpio22", "gpio23";
				function = "blsp_i2c6";

				drive-strength = <2>;
				bias-disable;
			};

			i2c6_sleep: i2c6-sleep {
				pins = "gpio22", "gpio23";
				function = "gpio";

				drive-strength = <2>;
				bias-disable;
			};

			pmx-sdc1-clk {
				sdc1_clk_on: clk-on {
					pins = "sdc1_clk";

					bias-disable;
					drive-strength = <16>;
				};
				sdc1_clk_off: clk-off {
					pins = "sdc1_clk";

					bias-disable;
					drive-strength = <2>;
				};
			};

			pmx-sdc1-cmd {
				sdc1_cmd_on: cmd-on {
					pins = "sdc1_cmd";

					bias-pull-up;
					drive-strength = <10>;
				};
				sdc1_cmd_off: cmd-off {
					pins = "sdc1_cmd";

					bias-pull-up;
					drive-strength = <2>;
				};
			};

			pmx-sdc1-data {
				sdc1_data_on: data-on {
					pins = "sdc1_data";

					bias-pull-up;
					drive-strength = <10>;
				};
				sdc1_data_off: data-off {
					pins = "sdc1_data";

					bias-pull-up;
					drive-strength = <2>;
				};
			};

			pmx-sdc2-clk {
				sdc2_clk_on: clk-on {
					pins = "sdc2_clk";

					bias-disable;
					drive-strength = <16>;
				};
				sdc2_clk_off: clk-off {
					pins = "sdc2_clk";

					bias-disable;
					drive-strength = <2>;
				};
			};

			pmx-sdc2-cmd {
				sdc2_cmd_on: cmd-on {
					pins = "sdc2_cmd";

					bias-pull-up;
					drive-strength = <10>;
				};
				sdc2_cmd_off: cmd-off {
					pins = "sdc2_cmd";

					bias-pull-up;
					drive-strength = <2>;
				};
			};

			pmx-sdc2-data {
				sdc2_data_on: data-on {
					pins = "sdc2_data";

					bias-pull-up;
					drive-strength = <10>;
				};
				sdc2_data_off: data-off {
					pins = "sdc2_data";

					bias-pull-up;
					drive-strength = <2>;
				};
			};

			pmx-sdc2-cd-pin {
				sdc2_cd_on: cd-on {
					pins = "gpio38";
					function = "gpio";

					drive-strength = <2>;
					bias-pull-up;
				};
				sdc2_cd_off: cd-off {
					pins = "gpio38";
					function = "gpio";

					drive-strength = <2>;
					bias-disable;
				};
			};

			spi1_default: spi1-default {
				pins = "gpio0", "gpio1", "gpio3";
				function = "blsp_spi1";

				drive-strength = <12>;
				bias-disable;

				cs {
					pins = "gpio2";
					function = "gpio";

					drive-strength = <16>;
					bias-disable;
					output-high;
				};
			};

			spi1_sleep: spi1-sleep {
				pins = "gpio0", "gpio1", "gpio2", "gpio3";
				function = "gpio";

				drive-strength = <2>;
				bias-pull-down;
			};

			spi2_default: spi2-default {
				pins = "gpio4", "gpio5", "gpio7";
				function = "blsp_spi2";

				drive-strength = <12>;
				bias-disable;

				cs {
					pins = "gpio6";
					function = "gpio";

					drive-strength = <16>;
					bias-disable;
					output-high;
				};
			};

			spi2_sleep: spi2-sleep {
				pins = "gpio4", "gpio5", "gpio6", "gpio7";
				function = "gpio";

				drive-strength = <2>;
				bias-pull-down;
			};

			spi3_default: spi3-default {
				pins = "gpio8", "gpio9", "gpio11";
				function = "blsp_spi3";

				drive-strength = <12>;
				bias-disable;

				cs {
					pins = "gpio10";
					function = "gpio";

					drive-strength = <16>;
					bias-disable;
					output-high;
				};
			};

			spi3_sleep: spi3-sleep {
				pins = "gpio8", "gpio9", "gpio10", "gpio11";
				function = "gpio";

				drive-strength = <2>;
				bias-pull-down;
			};

			spi4_default: spi4-default {
				pins = "gpio12", "gpio13", "gpio15";
				function = "blsp_spi4";

				drive-strength = <12>;
				bias-disable;

				cs {
					pins = "gpio14";
					function = "gpio";

					drive-strength = <16>;
					bias-disable;
					output-high;
				};
			};

			spi4_sleep: spi4-sleep {
				pins = "gpio12", "gpio13", "gpio14", "gpio15";
				function = "gpio";

				drive-strength = <2>;
				bias-pull-down;
			};

			spi5_default: spi5-default {
				pins = "gpio16", "gpio17", "gpio19";
				function = "blsp_spi5";

				drive-strength = <12>;
				bias-disable;

				cs {
					pins = "gpio18";
					function = "gpio";

					drive-strength = <16>;
					bias-disable;
					output-high;
				};
			};

			spi5_sleep: spi5-sleep {
				pins = "gpio16", "gpio17", "gpio18", "gpio19";
				function = "gpio";

				drive-strength = <2>;
				bias-pull-down;
			};

			spi6_default: spi6-default {
				pins = "gpio20", "gpio21", "gpio23";
				function = "blsp_spi6";

				drive-strength = <12>;
				bias-disable;

				cs {
					pins = "gpio22";
					function = "gpio";

					drive-strength = <16>;
					bias-disable;
					output-high;
				};
			};

			spi6_sleep: spi6-sleep {
				pins = "gpio20", "gpio21", "gpio22", "gpio23";
				function = "gpio";

				drive-strength = <2>;
				bias-pull-down;
			};

			wcnss_pin_a: wcnss-active {
				pins = "gpio40", "gpio41", "gpio42", "gpio43", "gpio44";
				function = "wcss_wlan";

				drive-strength = <6>;
				bias-pull-up;
			};

		};

		gcc: clock-controller@1800000 {
			compatible = "qcom,gcc-msm8939";
			#clock-cells = <1>;
			#reset-cells = <1>;
			#power-domain-cells = <1>;
			reg = <0x01800000 0x80000>;
			clock-names = "xo",
				      "sleep_clk";
			clocks = <&xo_board>,
				 <&sleep_clk>;
		};

		tcsr_mutex: hwlock@1905000 {
			compatible = "qcom,tcsr-mutex";
			reg = <0x01905000 0x20000>;
			#hwlock-cells = <1>;
		};

		tcsr: syscon@1937000 {
			compatible = "qcom,tcsr-msm8916", "syscon";
			reg = <0x01937000 0x30000>;
		};

		mdss: mdss@1a00000 {
			compatible = "qcom,mdss";
			reg = <0x01a00000 0x1000>,
			      <0x01ac8000 0x3000>;
			reg-names = "mdss_phys", "vbif_phys";

			interrupts = <GIC_SPI 72 IRQ_TYPE_LEVEL_HIGH>;
			interrupt-controller;

			clocks = <&gcc GCC_MDSS_AHB_CLK>,
				 <&gcc GCC_MDSS_AXI_CLK>,
				 <&gcc GCC_MDSS_VSYNC_CLK>;
			clock-names = "iface",
				      "bus",
				      "vsync";

			power-domains = <&gcc MDSS_GDSC>;

			#address-cells = <1>;
			#size-cells = <1>;
			#interrupt-cells = <1>;
			ranges;

			mdss_mdp: mdp@1a01000 {
				compatible = "qcom,mdp5";
				reg = <0x01a01000 0x89000>;
				reg-names = "mdp_phys";

				interrupt-parent = <&mdss>;
				interrupts = <0>;

				clocks = <&gcc GCC_MDSS_AHB_CLK>,
					 <&gcc GCC_MDSS_AXI_CLK>,
					 <&gcc GCC_MDSS_MDP_CLK>,
					 <&gcc GCC_MDSS_VSYNC_CLK>,
					 <&gcc GCC_MDP_TBU_CLK>,
					 <&gcc GCC_MDP_RT_TBU_CLK>;
				clock-names = "iface",
					      "bus",
					      "core",
					      "vsync",
					      "tbu",
					      "tbu_rt";

				iommus = <&apps_iommu 4>;

				interconnects = <&snoc_mm MASTER_MDP_PORT0 &bimc SLAVE_EBI_CH0>,
						<&snoc_mm MASTER_MDP_PORT1 &bimc SLAVE_EBI_CH0>;
				interconnect-names = "mdp0-mem", "mdp1-mem";

				ports {
					#address-cells = <1>;
					#size-cells = <0>;

					port@0 {
						reg = <0>;
						mdp5_intf1_out: endpoint {
							remote-endpoint = <&dsi0_in>;
						};
					};

					port@1 {
						reg = <1>;
						mdp5_intf2_out: endpoint {
							remote-endpoint = <&dsi1_in>;
						};
					};
				};
			};


			mdss_dsi0: dsi@1a98000 {
				compatible = "qcom,mdss-dsi-ctrl";
				reg = <0x01a98000 0x25c>;
				reg-names = "dsi_ctrl";

				interrupt-parent = <&mdss>;
				interrupts = <4>;

				clocks = <&gcc GCC_MDSS_MDP_CLK>,
					 <&gcc GCC_MDSS_AHB_CLK>,
					 <&gcc GCC_MDSS_AXI_CLK>,
					 <&gcc GCC_MDSS_BYTE0_CLK>,
					 <&gcc GCC_MDSS_PCLK0_CLK>,
					 <&gcc GCC_MDSS_ESC0_CLK>;
				clock-names = "mdp_core",
					      "iface",
					      "bus",
					      "byte",
					      "pixel",
					      "core";
				assigned-clocks = <&gcc BYTE0_CLK_SRC>,
						  <&gcc PCLK0_CLK_SRC>;
				assigned-clock-parents = <&mdss_dsi0_phy 0>,
							 <&mdss_dsi0_phy 1>;

				phys = <&mdss_dsi0_phy>;
				phy-names = "dsi-phy";
				status = "disabled";

				#address-cells = <1>;
				#size-cells = <0>;

				ports {
					#address-cells = <1>;
					#size-cells = <0>;

					port@0 {
						reg = <0>;
						dsi0_in: endpoint {
							remote-endpoint = <&mdp5_intf1_out>;
						};
					};

					port@1 {
						reg = <1>;
						dsi0_out: endpoint {
						};
					};
				};
			};

			mdss_dsi0_phy: dsi-phy@1a98300 {
				compatible = "qcom,dsi-phy-28nm-lp";
				reg = <0x01a98300 0xd4>,
				      <0x01a98500 0x280>,
				      <0x01a98780 0x30>;
				reg-names = "dsi_pll",
					    "dsi_phy",
					    "dsi_phy_regulator";

				clocks = <&gcc GCC_MDSS_AHB_CLK>,
					 <&xo_board>;
				clock-names = "iface", "ref";

				#clock-cells = <1>;
				#phy-cells = <0>;

				qcom,dsi-phy-regulator-ldo-mode;
				status = "disabled";
			};

			mdss_dsi1: dsi@1aa0000 {
				compatible = "qcom,mdss-dsi-ctrl";
				reg = <0x01aa0000 0x25c>;
				reg-names = "dsi_ctrl";

				interrupt-parent = <&mdss>;
				interrupts = <5>;

				clocks = <&gcc GCC_MDSS_MDP_CLK>,
					 <&gcc GCC_MDSS_AHB_CLK>,
					 <&gcc GCC_MDSS_AXI_CLK>,
					 <&gcc GCC_MDSS_BYTE1_CLK>,
					 <&gcc GCC_MDSS_PCLK1_CLK>,
					 <&gcc GCC_MDSS_ESC1_CLK>;
				clock-names = "mdp_core",
					      "iface",
					      "bus",
					      "byte",
					      "pixel",
					      "core";

				assigned-clocks = <&gcc BYTE1_CLK_SRC>,
						  <&gcc PCLK1_CLK_SRC>;
				assigned-clock-parents = <&mdss_dsi1_phy 0>,
							 <&mdss_dsi1_phy 1>;
				phys = <&mdss_dsi1_phy>;
				phy-names = "dsi-phy";
				status = "disabled";

				ports {
					#address-cells = <1>;
					#size-cells = <0>;

					port@0 {
						reg = <0>;
						dsi1_in: endpoint {
							remote-endpoint = <&mdp5_intf2_out>;
						};
					};

					port@1 {
						reg = <1>;
						dsi1_out: endpoint {
						};
					};
				};
			};

			mdss_dsi1_phy: dsi-phy@1aa0300 {
				compatible = "qcom,dsi-phy-28nm-lp";
				reg = <0x01aa0300 0xd4>,
				      <0x01aa0500 0x280>,
				      <0x01aa0780 0x30>;
				reg-names = "dsi_pll",
					    "dsi_phy",
					    "dsi_phy_regulator";

				clocks = <&gcc GCC_MDSS_AHB_CLK>,
					 <&xo_board>;
				clock-names = "iface", "ref";

				#clock-cells = <1>;
				#phy-cells = <0>;
				qcom,dsi-phy-regulator-ldo-mode;
				status = "disabled";
			};
		};

		camss: camss@1b00000 {
			compatible = "qcom,msm8916-camss";
			reg = <0x01b0ac00 0x200>,
				<0x01b00030 0x4>,
				<0x01b0b000 0x200>,
				<0x01b00038 0x4>,
				<0x01b08000 0x100>,
				<0x01b08400 0x100>,
				<0x01b0a000 0x500>,
				<0x01b00020 0x10>,
				<0x01b10000 0x1000>;
			reg-names = "csiphy0",
				"csiphy0_clk_mux",
				"csiphy1",
				"csiphy1_clk_mux",
				"csid0",
				"csid1",
				"ispif",
				"csi_clk_mux",
				"vfe0";
			interrupts = <GIC_SPI 78 IRQ_TYPE_EDGE_RISING>,
				<GIC_SPI 79 IRQ_TYPE_EDGE_RISING>,
				<GIC_SPI 51 IRQ_TYPE_EDGE_RISING>,
				<GIC_SPI 52 IRQ_TYPE_EDGE_RISING>,
				<GIC_SPI 55 IRQ_TYPE_EDGE_RISING>,
				<GIC_SPI 57 IRQ_TYPE_EDGE_RISING>;
			interrupt-names = "csiphy0",
				"csiphy1",
				"csid0",
				"csid1",
				"ispif",
				"vfe0";
			power-domains = <&gcc VFE_GDSC>;
			clocks = <&gcc GCC_CAMSS_TOP_AHB_CLK>,
				<&gcc GCC_CAMSS_ISPIF_AHB_CLK>,
				<&gcc GCC_CAMSS_CSI0PHYTIMER_CLK>,
				<&gcc GCC_CAMSS_CSI1PHYTIMER_CLK>,
				<&gcc GCC_CAMSS_CSI0_AHB_CLK>,
				<&gcc GCC_CAMSS_CSI0_CLK>,
				<&gcc GCC_CAMSS_CSI0PHY_CLK>,
				<&gcc GCC_CAMSS_CSI0PIX_CLK>,
				<&gcc GCC_CAMSS_CSI0RDI_CLK>,
				<&gcc GCC_CAMSS_CSI1_AHB_CLK>,
				<&gcc GCC_CAMSS_CSI1_CLK>,
				<&gcc GCC_CAMSS_CSI1PHY_CLK>,
				<&gcc GCC_CAMSS_CSI1PIX_CLK>,
				<&gcc GCC_CAMSS_CSI1RDI_CLK>,
				<&gcc GCC_CAMSS_AHB_CLK>,
				<&gcc GCC_CAMSS_VFE0_CLK>,
				<&gcc GCC_CAMSS_CSI_VFE0_CLK>,
				<&gcc GCC_CAMSS_VFE_AHB_CLK>,
				<&gcc GCC_CAMSS_VFE_AXI_CLK>;
			clock-names = "top_ahb",
				"ispif_ahb",
				"csiphy0_timer",
				"csiphy1_timer",
				"csi0_ahb",
				"csi0",
				"csi0_phy",
				"csi0_pix",
				"csi0_rdi",
				"csi1_ahb",
				"csi1",
				"csi1_phy",
				"csi1_pix",
				"csi1_rdi",
				"ahb",
				"vfe0",
				"csi_vfe0",
				"vfe_ahb",
				"vfe_axi";
			iommus = <&apps_iommu 3>;
			status = "disabled";
			ports {
				#address-cells = <1>;
				#size-cells = <0>;
			};
		};

		cci: cci@1b0c000 {
			compatible = "qcom,msm8916-cci";
			#address-cells = <1>;
			#size-cells = <0>;
			reg = <0x01b0c000 0x1000>;
			interrupts = <GIC_SPI 50 IRQ_TYPE_EDGE_RISING>;
			clocks = <&gcc GCC_CAMSS_ISPIF_AHB_CLK>,
				<&gcc GCC_CAMSS_TOP_AHB_CLK>,
				<&gcc GCC_CAMSS_CCI_AHB_CLK>,
				<&gcc GCC_CAMSS_CCI_CLK>,
				<&gcc GCC_CAMSS_AHB_CLK>;
			clock-names = "ispif_ahb","camss_top_ahb", "cci_ahb",
					  "cci", "camss_ahb";
			assigned-clocks = <&gcc GCC_CAMSS_ISPIF_AHB_CLK>,
					  <&gcc GCC_CAMSS_CCI_CLK>;
			assigned-clock-rates = <80000000>, <19200000>;
			pinctrl-names = "default";
			pinctrl-0 = <&cci0_default>;
			status = "disabled";

			cci_i2c0: i2c-bus@0 {
				reg = <0>;
				clock-frequency = <400000>;
				#address-cells = <1>;
				#size-cells = <0>;
			};
		};

		gpu@1c00000 {
			compatible = "qcom,adreno-405.0", "qcom,adreno";
			reg = <0x01c00000 0x10000>;
			reg-names = "kgsl_3d0_reg_memory";
			interrupts = <GIC_SPI 33 IRQ_TYPE_LEVEL_HIGH>;
			interrupt-names = "kgsl_3d0_irq";
			vdd-supply = <>;
                        vcc-supply = <>;
			clock-names = "core",
				      "iface",
				      "mem",
				      "mem_iface",
				      "alt_mem_iface",
				      "gfx3d",
				      "rbbmtimer";
			clocks = <&gcc GCC_OXILI_GFX3D_CLK>,
				 <&gcc GCC_OXILI_AHB_CLK>,
				 <&gcc GCC_OXILI_GMEM_CLK>,
				 <&gcc GCC_BIMC_GFX_CLK>,
				 <&gcc GCC_BIMC_GPU_CLK>,
				 <&gcc GFX3D_CLK_SRC>,
				 <&gcc GCC_OXILI_TIMER_CLK>;
			power-domains = <&gcc OXILI_GDSC>;
			operating-points-v2 = <&opp_table>;
			iommus = <&gpu_iommu 1>, <&gpu_iommu 2>;

			opp_table: opp-table {
				compatible = "operating-points-v2";

				opp-550000000 {
					opp-hz = /bits/ 64 <550000000>;
				};

				opp-465000000 {
					opp-hz = /bits/ 64 <465000000>;
				};

				opp-400000000 {
					opp-hz = /bits/ 64 <400000000>;
				};

				opp-220000000 {
					opp-hz = /bits/ 64 <220000000>;
				};

				opp-19200000 {
					opp-hz = /bits/ 64 <19200000>;
				};
			};
		};

		venus: video-codec@1d00000 {
			compatible = "qcom,msm8916-venus";
			reg = <0x01d00000 0xff000>;
			interrupts = <GIC_SPI 44 IRQ_TYPE_LEVEL_HIGH>;
			power-domains = <&gcc VENUS_GDSC>;
			clocks = <&gcc GCC_VENUS0_VCODEC0_CLK>,
				 <&gcc GCC_VENUS0_AHB_CLK>,
				 <&gcc GCC_VENUS0_AXI_CLK>;
			clock-names = "core", "iface", "bus";
			iommus = <&apps_iommu 5>;
			memory-region = <&venus_mem>;
			status = "okay";

			video-decoder {
				compatible = "venus-decoder";
			};

			video-encoder {
				compatible = "venus-encoder";
			};
		};

		apps_iommu: iommu@1ef0000 {
			#address-cells = <1>;
			#size-cells = <1>;
			#iommu-cells = <1>;
			compatible = "qcom,msm8916-iommu", "qcom,msm-iommu-v1";
			ranges = <0 0x01e20000 0x40000>;
			reg = <0x01ef0000 0x3000>;
			clocks = <&gcc GCC_SMMU_CFG_CLK>,
				 <&gcc GCC_APSS_TCU_CLK>;
			clock-names = "iface", "bus";
			qcom,iommu-secure-id = <17>;

			// vfe:
			iommu-ctx@3000 {
				compatible = "qcom,msm-iommu-v1-sec";
				reg = <0x3000 0x1000>;
				interrupts = <GIC_SPI 70 IRQ_TYPE_LEVEL_HIGH>;
			};

			// mdp_0:
			iommu-ctx@4000 {
				compatible = "qcom,msm-iommu-v1-ns";
				reg = <0x4000 0x1000>;
				interrupts = <GIC_SPI 70 IRQ_TYPE_LEVEL_HIGH>;
			};

			// venus_ns:
			iommu-ctx@5000 {
				compatible = "qcom,msm-iommu-v1-sec";
				reg = <0x5000 0x1000>;
				interrupts = <GIC_SPI 70 IRQ_TYPE_LEVEL_HIGH>;
			};
		};

		gpu_iommu: iommu@1f08000 {
			#address-cells = <1>;
			#size-cells = <1>;
			#iommu-cells = <1>;
			compatible = "qcom,msm8916-iommu", "qcom,msm-iommu-v1";
			ranges = <0 0x01f08000 0x10000>;
			clocks = <&gcc GCC_SMMU_CFG_CLK>,
				 <&gcc GCC_GFX_TCU_CLK>,
				 <&gcc GCC_GFX_TBU_CLK>;
			clock-names = "iface", "bus", "tbu";
			qcom,iommu-secure-id = <18>;

			// gfx3d_user:
			iommu-ctx@1000 {
				compatible = "qcom,msm-iommu-v1-ns";
				reg = <0x1000 0x1000>;
				interrupts = <GIC_SPI 241 IRQ_TYPE_LEVEL_HIGH>;
			};

			// gfx3d_priv:
			iommu-ctx@2000 {
				compatible = "qcom,msm-iommu-v1-ns";
				reg = <0x2000 0x1000>;
				interrupts = <GIC_SPI 242 IRQ_TYPE_LEVEL_HIGH>;
			};
		};

		spmi_bus: spmi@200f000 {
			compatible = "qcom,spmi-pmic-arb";
			reg = <0x0200f000 0x001000>,
			      <0x02400000 0x400000>,
			      <0x02c00000 0x400000>,
			      <0x03800000 0x200000>,
			      <0x0200a000 0x002100>;
			reg-names = "core", "chnls", "obsrvr", "intr", "cnfg";
			interrupt-names = "periph_irq";
			interrupts = <GIC_SPI 190 IRQ_TYPE_LEVEL_HIGH>;
			qcom,ee = <0>;
			qcom,channel = <0>;
			#address-cells = <2>;
			#size-cells = <0>;
			interrupt-controller;
			#interrupt-cells = <4>;
		};

		bam_dmux_dma: dma-controller@4044000 {
			compatible = "qcom,bam-v1.7.0";
			reg = <0x04044000 0x19000>;
			interrupts = <GIC_SPI 29 IRQ_TYPE_LEVEL_HIGH>;
			#dma-cells = <1>;
			qcom,ee = <0>;

			num-channels = <6>;
			qcom,num-ees = <1>;
			qcom,powered-remotely;

			status = "disabled";
		};

		mpss: remoteproc@4080000 {
			compatible = "qcom,msm8916-mss-pil", "qcom,q6v5-pil";
			reg = <0x04080000 0x100>,
			      <0x04020000 0x040>;

			reg-names = "qdsp6", "rmb";

			interrupts-extended = <&intc GIC_SPI 24 IRQ_TYPE_EDGE_RISING>,
					      <&hexagon_smp2p_in 0 IRQ_TYPE_EDGE_RISING>,
					      <&hexagon_smp2p_in 1 IRQ_TYPE_EDGE_RISING>,
					      <&hexagon_smp2p_in 2 IRQ_TYPE_EDGE_RISING>,
					      <&hexagon_smp2p_in 3 IRQ_TYPE_EDGE_RISING>;
			interrupt-names = "wdog", "fatal", "ready",
					  "handover", "stop-ack";

			power-domains = <&rpmpd MSM8939_VDDMDCX_AO>,
					<&rpmpd MSM8939_VDDMX>;
			power-domain-names = "cx", "mx";

			clocks = <&gcc GCC_MSS_CFG_AHB_CLK>,
				 <&gcc GCC_MSS_Q6_BIMC_AXI_CLK>,
				 <&gcc GCC_BOOT_ROM_AHB_CLK>,
				 <&xo_board>;
			clock-names = "iface", "bus", "mem", "xo";

			qcom,smem-states = <&hexagon_smp2p_out 0>;
			qcom,smem-state-names = "stop";

			resets = <&scm 0>;
			reset-names = "mss_restart";

			qcom,halt-regs = <&tcsr 0x18000 0x19000 0x1a000>;

			status = "disabled";

			mba {
				memory-region = <&mba_mem>;
			};

			mpss {
				memory-region = <&mpss_mem>;
			};

			bam_dmux: bam-dmux {
				compatible = "qcom,bam-dmux";

				interrupt-parent = <&hexagon_smsm>;
				interrupts = <1 IRQ_TYPE_EDGE_BOTH>, <11 IRQ_TYPE_EDGE_BOTH>;
				interrupt-names = "pc", "pc-ack";

				qcom,smem-states = <&apps_smsm 1>, <&apps_smsm 11>;
				qcom,smem-state-names = "pc", "pc-ack";

				dmas = <&bam_dmux_dma 4>, <&bam_dmux_dma 5>;
				dma-names = "tx", "rx";

				status = "disabled";
			};

			smd-edge {
				interrupts = <GIC_SPI 25 IRQ_TYPE_EDGE_RISING>;

				qcom,smd-edge = <0>;
				mboxes = <&apcs_mbox 12>;
				qcom,remote-pid = <1>;

				label = "hexagon";

				apr: apr {
					compatible = "qcom,apr-v2";
					qcom,smd-channels = "apr_audio_svc";
					qcom,apr-domain = <APR_DOMAIN_ADSP>;
					#address-cells = <1>;
					#size-cells = <0>;
					status = "disabled";

					apr-service@3 {
						reg = <APR_SVC_ADSP_CORE>;
						compatible = "qcom,q6core";
					};

					q6afe: apr-service@4 {
						compatible = "qcom,q6afe";
						reg = <APR_SVC_AFE>;
						q6afedai: dais {
							compatible = "qcom,q6afe-dais";
							#address-cells = <1>;
							#size-cells = <0>;
							#sound-dai-cells = <1>;
						};
					};

					q6asm: apr-service@7 {
						compatible = "qcom,q6asm";
						reg = <APR_SVC_ASM>;
						q6asmdai: dais {
							compatible = "qcom,q6asm-dais";
							#address-cells = <1>;
							#size-cells = <0>;
							#sound-dai-cells = <1>;
						};
					};

					q6adm: apr-service@8 {
						compatible = "qcom,q6adm";
						reg = <APR_SVC_ADM>;
						q6routing: routing {
							compatible = "qcom,q6adm-routing";
							#sound-dai-cells = <0>;
						};
					};

					q6mvm: apr-service@9 {
						compatible = "qcom,q6mvm";
						reg = <APR_SVC_ADSP_MVM>;

						q6voicedai: dais {
							compatible = "qcom,q6voice-dais";
							#sound-dai-cells = <0>;
						};
					};

					q6cvs: apr-service@a {
						compatible = "qcom,q6cvs";
						reg = <APR_SVC_ADSP_CVS>;
					};

					q6cvp: apr-service@b {
						compatible = "qcom,q6cvp";
						reg = <APR_SVC_ADSP_CVP>;
					};
				};

				fastrpc {
					compatible = "qcom,fastrpc";
					qcom,smd-channels = "fastrpcsmd-apps-dsp";
					label = "adsp";

					#address-cells = <1>;
					#size-cells = <0>;

					cb@1 {
						compatible = "qcom,fastrpc-compute-cb";
						reg = <1>;
					};
				};
			};
		};

		sound: sound@7702000 {
			status = "disabled";
			compatible = "qcom,apq8016-sbc-sndcard";
			reg = <0x07702000 0x4>, <0x07702004 0x4>;
			reg-names = "mic-iomux", "spkr-iomux";
		};

		lpass: audio-controller@7708000 {
			status = "disabled";
			compatible = "qcom,lpass-cpu-apq8016";

			/*
			 * Note: Unlike the name would suggest, the SEC_I2S_CLK
			 * is actually only used by Tertiary MI2S while
			 * Primary/Secondary MI2S both use the PRI_I2S_CLK.
			 */
			clocks = <&gcc GCC_ULTAUDIO_AHBFABRIC_IXFABRIC_CLK>,
				 <&gcc GCC_ULTAUDIO_PCNOC_MPORT_CLK>,
				 <&gcc GCC_ULTAUDIO_PCNOC_SWAY_CLK>,
				 <&gcc GCC_ULTAUDIO_LPAIF_PRI_I2S_CLK>,
				 <&gcc GCC_ULTAUDIO_LPAIF_PRI_I2S_CLK>,
				 <&gcc GCC_ULTAUDIO_LPAIF_SEC_I2S_CLK>,
				 <&gcc GCC_ULTAUDIO_LPAIF_AUX_I2S_CLK>;

			clock-names = "ahbix-clk",
					"pcnoc-mport-clk",
					"pcnoc-sway-clk",
					"mi2s-bit-clk0",
					"mi2s-bit-clk1",
					"mi2s-bit-clk2",
					"mi2s-bit-clk3";
			#sound-dai-cells = <1>;

			interrupts = <GIC_SPI 160 IRQ_TYPE_LEVEL_HIGH>;
			interrupt-names = "lpass-irq-lpaif";
			reg = <0x07708000 0x10000>;
			reg-names = "lpass-lpaif";

			#address-cells = <1>;
			#size-cells = <0>;
		};

		lpass_codec: audio-codec@771c000 {
			compatible = "qcom,msm8916-wcd-digital-codec";
			reg = <0x0771c000 0x400>;
			clocks = <&gcc GCC_ULTAUDIO_AHBFABRIC_IXFABRIC_CLK>,
				 <&gcc GCC_CODEC_DIGCODEC_CLK>;
			clock-names = "ahbix-clk", "mclk";
			#sound-dai-cells = <1>;
		};

		sdhc_1: sdhci@7824000 {
			compatible = "qcom,msm8916-sdhci", "qcom,sdhci-msm-v4";
			reg = <0x07824900 0x11c>, <0x07824000 0x800>;
			reg-names = "hc_mem", "core_mem";

			interrupts = <GIC_SPI 123 IRQ_TYPE_LEVEL_HIGH>,
				     <GIC_SPI 138 IRQ_TYPE_LEVEL_HIGH>;
			interrupt-names = "hc_irq", "pwr_irq";
			clocks = <&gcc GCC_SDCC1_APPS_CLK>,
				 <&gcc GCC_SDCC1_AHB_CLK>,
				 <&xo_board>;
			clock-names = "core", "iface", "xo";
			mmc-hs200-1_8v;
			bus-width = <8>;
			non-removable;
			status = "disabled";
		};

		sdhc_2: sdhci@7864000 {
			compatible = "qcom,msm8916-sdhci", "qcom,sdhci-msm-v4";
			reg = <0x07864900 0x11c>, <0x07864000 0x800>;
			reg-names = "hc_mem", "core_mem";

			interrupts = <GIC_SPI 125 IRQ_TYPE_LEVEL_HIGH>,
				     <GIC_SPI 221 IRQ_TYPE_LEVEL_HIGH>;
			interrupt-names = "hc_irq", "pwr_irq";
			clocks = <&gcc GCC_SDCC2_APPS_CLK>,
				 <&gcc GCC_SDCC2_AHB_CLK>,
				 <&xo_board>;
			clock-names = "core", "iface", "xo";
			bus-width = <4>;
			status = "disabled";
		};

		blsp_dma: dma-controller@7884000 {
			compatible = "qcom,bam-v1.7.0";
			reg = <0x07884000 0x23000>;
			interrupts = <GIC_SPI 238 IRQ_TYPE_LEVEL_HIGH>;
			clocks = <&gcc GCC_BLSP1_AHB_CLK>;
			clock-names = "bam_clk";
			#dma-cells = <1>;
			qcom,ee = <0>;
			status = "disabled";
		};

		blsp1_uart1: serial@78af000 {
			compatible = "qcom,msm-uartdm-v1.4", "qcom,msm-uartdm";
			reg = <0x078af000 0x200>;
			interrupts = <GIC_SPI 107 IRQ_TYPE_LEVEL_HIGH>;
			clocks = <&gcc GCC_BLSP1_UART1_APPS_CLK>, <&gcc GCC_BLSP1_AHB_CLK>;
			clock-names = "core", "iface";
			dmas = <&blsp_dma 1>, <&blsp_dma 0>;
			dma-names = "rx", "tx";
			pinctrl-names = "default", "sleep";
			pinctrl-0 = <&blsp1_uart1_default>;
			pinctrl-1 = <&blsp1_uart1_sleep>;
			status = "disabled";
		};

		blsp1_uart2: serial@78b0000 {
			compatible = "qcom,msm-uartdm-v1.4", "qcom,msm-uartdm";
			reg = <0x078b0000 0x200>;
			interrupts = <GIC_SPI 108 IRQ_TYPE_LEVEL_HIGH>;
			clocks = <&gcc GCC_BLSP1_UART2_APPS_CLK>, <&gcc GCC_BLSP1_AHB_CLK>;
			clock-names = "core", "iface";
			dmas = <&blsp_dma 3>, <&blsp_dma 2>;
			dma-names = "rx", "tx";
			pinctrl-names = "default", "sleep";
			pinctrl-0 = <&blsp1_uart2_default>;
			pinctrl-1 = <&blsp1_uart2_sleep>;
			status = "disabled";
		};

		blsp_i2c1: i2c@78b5000 {
			compatible = "qcom,i2c-qup-v2.2.1";
			reg = <0x078b5000 0x500>;
			interrupts = <GIC_SPI 95 IRQ_TYPE_LEVEL_HIGH>;
			clocks = <&gcc GCC_BLSP1_AHB_CLK>,
				 <&gcc GCC_BLSP1_QUP1_I2C_APPS_CLK>;
			clock-names = "iface", "core";
			dmas = <&blsp_dma 5>, <&blsp_dma 4>;
			dma-names = "rx", "tx";
			pinctrl-names = "default", "sleep";
			pinctrl-0 = <&i2c1_default>;
			pinctrl-1 = <&i2c1_sleep>;
			#address-cells = <1>;
			#size-cells = <0>;
			status = "disabled";
		};

		blsp_spi1: spi@78b5000 {
			compatible = "qcom,spi-qup-v2.2.1";
			reg = <0x078b5000 0x500>;
			interrupts = <GIC_SPI 95 IRQ_TYPE_LEVEL_HIGH>;
			clocks = <&gcc GCC_BLSP1_QUP1_SPI_APPS_CLK>,
				 <&gcc GCC_BLSP1_AHB_CLK>;
			clock-names = "core", "iface";
			dmas = <&blsp_dma 5>, <&blsp_dma 4>;
			dma-names = "rx", "tx";
			pinctrl-names = "default", "sleep";
			pinctrl-0 = <&spi1_default>;
			pinctrl-1 = <&spi1_sleep>;
			#address-cells = <1>;
			#size-cells = <0>;
			status = "disabled";
		};

		blsp_i2c2: i2c@78b6000 {
			compatible = "qcom,i2c-qup-v2.2.1";
			reg = <0x078b6000 0x500>;
			interrupts = <GIC_SPI 96 IRQ_TYPE_LEVEL_HIGH>;
			clocks = <&gcc GCC_BLSP1_AHB_CLK>,
				 <&gcc GCC_BLSP1_QUP2_I2C_APPS_CLK>;
			clock-names = "iface", "core";
			dmas = <&blsp_dma 7>, <&blsp_dma 6>;
			dma-names = "rx", "tx";
			pinctrl-names = "default", "sleep";
			pinctrl-0 = <&i2c2_default>;
			pinctrl-1 = <&i2c2_sleep>;
			#address-cells = <1>;
			#size-cells = <0>;
			status = "disabled";
		};

		blsp_spi2: spi@78b6000 {
			compatible = "qcom,spi-qup-v2.2.1";
			reg = <0x078b6000 0x500>;
			interrupts = <GIC_SPI 96 IRQ_TYPE_LEVEL_HIGH>;
			clocks = <&gcc GCC_BLSP1_QUP2_SPI_APPS_CLK>,
				 <&gcc GCC_BLSP1_AHB_CLK>;
			clock-names = "core", "iface";
			dmas = <&blsp_dma 7>, <&blsp_dma 6>;
			dma-names = "rx", "tx";
			pinctrl-names = "default", "sleep";
			pinctrl-0 = <&spi2_default>;
			pinctrl-1 = <&spi2_sleep>;
			#address-cells = <1>;
			#size-cells = <0>;
			status = "disabled";
		};

		blsp_i2c3: i2c@78b7000 {
			compatible = "qcom,i2c-qup-v2.2.1";
			reg = <0x078b7000 0x500>;
			interrupts = <GIC_SPI 97 IRQ_TYPE_LEVEL_HIGH>;
			clocks = <&gcc GCC_BLSP1_AHB_CLK>,
				 <&gcc GCC_BLSP1_QUP3_I2C_APPS_CLK>;
			clock-names = "iface", "core";
			dmas = <&blsp_dma 9>, <&blsp_dma 8>;
			dma-names = "rx", "tx";
			pinctrl-names = "default", "sleep";
			pinctrl-0 = <&i2c3_default>;
			pinctrl-1 = <&i2c3_sleep>;
			#address-cells = <1>;
			#size-cells = <0>;
			status = "disabled";
		};

		blsp_spi3: spi@78b7000 {
			compatible = "qcom,spi-qup-v2.2.1";
			reg = <0x078b7000 0x500>;
			interrupts = <GIC_SPI 97 IRQ_TYPE_LEVEL_HIGH>;
			clocks = <&gcc GCC_BLSP1_QUP3_SPI_APPS_CLK>,
				 <&gcc GCC_BLSP1_AHB_CLK>;
			clock-names = "core", "iface";
			dmas = <&blsp_dma 9>, <&blsp_dma 8>;
			dma-names = "rx", "tx";
			pinctrl-names = "default", "sleep";
			pinctrl-0 = <&spi3_default>;
			pinctrl-1 = <&spi3_sleep>;
			#address-cells = <1>;
			#size-cells = <0>;
			status = "disabled";
		};

		blsp_i2c4: i2c@78b8000 {
			compatible = "qcom,i2c-qup-v2.2.1";
			reg = <0x078b8000 0x500>;
			interrupts = <GIC_SPI 98 IRQ_TYPE_LEVEL_HIGH>;
			clocks = <&gcc GCC_BLSP1_AHB_CLK>,
				 <&gcc GCC_BLSP1_QUP4_I2C_APPS_CLK>;
			clock-names = "iface", "core";
			dmas = <&blsp_dma 11>, <&blsp_dma 10>;
			dma-names = "rx", "tx";
			pinctrl-names = "default", "sleep";
			pinctrl-0 = <&i2c4_default>;
			pinctrl-1 = <&i2c4_sleep>;
			#address-cells = <1>;
			#size-cells = <0>;
			status = "disabled";
		};

		blsp_spi4: spi@78b8000 {
			compatible = "qcom,spi-qup-v2.2.1";
			reg = <0x078b8000 0x500>;
			interrupts = <GIC_SPI 98 IRQ_TYPE_LEVEL_HIGH>;
			clocks = <&gcc GCC_BLSP1_QUP4_SPI_APPS_CLK>,
				 <&gcc GCC_BLSP1_AHB_CLK>;
			clock-names = "core", "iface";
			dmas = <&blsp_dma 11>, <&blsp_dma 10>;
			dma-names = "rx", "tx";
			pinctrl-names = "default", "sleep";
			pinctrl-0 = <&spi4_default>;
			pinctrl-1 = <&spi4_sleep>;
			#address-cells = <1>;
			#size-cells = <0>;
			status = "disabled";
		};

		blsp_i2c5: i2c@78b9000 {
			compatible = "qcom,i2c-qup-v2.2.1";
			reg = <0x078b9000 0x500>;
			interrupts = <GIC_SPI 99 IRQ_TYPE_LEVEL_HIGH>;
			clocks = <&gcc GCC_BLSP1_AHB_CLK>,
				 <&gcc GCC_BLSP1_QUP5_I2C_APPS_CLK>;
			clock-names = "iface", "core";
			dmas = <&blsp_dma 13>, <&blsp_dma 12>;
			dma-names = "rx", "tx";
			pinctrl-names = "default", "sleep";
			pinctrl-0 = <&i2c5_default>;
			pinctrl-1 = <&i2c5_sleep>;
			#address-cells = <1>;
			#size-cells = <0>;
			status = "disabled";
		};

		blsp_spi5: spi@78b9000 {
			compatible = "qcom,spi-qup-v2.2.1";
			reg = <0x078b9000 0x500>;
			interrupts = <GIC_SPI 99 IRQ_TYPE_LEVEL_HIGH>;
			clocks = <&gcc GCC_BLSP1_QUP5_SPI_APPS_CLK>,
				 <&gcc GCC_BLSP1_AHB_CLK>;
			clock-names = "core", "iface";
			dmas = <&blsp_dma 13>, <&blsp_dma 12>;
			dma-names = "rx", "tx";
			pinctrl-names = "default", "sleep";
			pinctrl-0 = <&spi5_default>;
			pinctrl-1 = <&spi5_sleep>;
			#address-cells = <1>;
			#size-cells = <0>;
			status = "disabled";
		};

		blsp_i2c6: i2c@78ba000 {
			compatible = "qcom,i2c-qup-v2.2.1";
			reg = <0x078ba000 0x500>;
			interrupts = <GIC_SPI 100 IRQ_TYPE_LEVEL_HIGH>;
			clocks = <&gcc GCC_BLSP1_AHB_CLK>,
				 <&gcc GCC_BLSP1_QUP6_I2C_APPS_CLK>;
			clock-names = "iface", "core";
			dmas = <&blsp_dma 15>, <&blsp_dma 14>;
			dma-names = "rx", "tx";
			pinctrl-names = "default", "sleep";
			pinctrl-0 = <&i2c6_default>;
			pinctrl-1 = <&i2c6_sleep>;
			#address-cells = <1>;
			#size-cells = <0>;
			status = "disabled";
		};

		blsp_spi6: spi@78ba000 {
			compatible = "qcom,spi-qup-v2.2.1";
			reg = <0x078ba000 0x500>;
			interrupts = <GIC_SPI 100 IRQ_TYPE_LEVEL_HIGH>;
			clocks = <&gcc GCC_BLSP1_QUP6_SPI_APPS_CLK>,
				 <&gcc GCC_BLSP1_AHB_CLK>;
			clock-names = "core", "iface";
			dmas = <&blsp_dma 15>, <&blsp_dma 14>;
			dma-names = "rx", "tx";
			pinctrl-names = "default", "sleep";
			pinctrl-0 = <&spi6_default>;
			pinctrl-1 = <&spi6_sleep>;
			#address-cells = <1>;
			#size-cells = <0>;
			status = "disabled";
		};

		usb: usb@78d9000 {
			compatible = "qcom,ci-hdrc";
			reg = <0x078d9000 0x200>,
			      <0x078d9200 0x200>;
			interrupts = <GIC_SPI 134 IRQ_TYPE_LEVEL_HIGH>,
				     <GIC_SPI 140 IRQ_TYPE_LEVEL_HIGH>;
			clocks = <&gcc GCC_USB_HS_AHB_CLK>,
				 <&gcc GCC_USB_HS_SYSTEM_CLK>;
			clock-names = "iface", "core";
			assigned-clocks = <&gcc GCC_USB_HS_SYSTEM_CLK>;
			assigned-clock-rates = <80000000>;
			resets = <&gcc GCC_USB_HS_BCR>;
			reset-names = "core";
			phy_type = "ulpi";
			dr_mode = "otg";
			hnp-disable;
			srp-disable;
			adp-disable;
			ahb-burst-config = <0>;
			phy-names = "usb-phy";
			phys = <&usb_hs_phy>;
			status = "disabled";
			#reset-cells = <1>;

			ulpi {
				usb_hs_phy: phy {
					compatible = "qcom,usb-hs-phy-msm8916",
						     "qcom,usb-hs-phy";
					#phy-cells = <0>;
					clocks = <&xo_board>, <&gcc GCC_USB2A_PHY_SLEEP_CLK>;
					clock-names = "ref", "sleep";
					resets = <&gcc GCC_USB2A_PHY_BCR>, <&usb 0>;
					reset-names = "phy", "por";
					qcom,init-seq = /bits/ 8 <0x0 0x44
						0x1 0x6b 0x2 0x24 0x3 0x13>;
				};
			};
		};

		pronto: remoteproc@a21b000 {
			compatible = "qcom,pronto-v2-pil", "qcom,pronto";
			reg = <0x0a204000 0x2000>, <0x0a202000 0x1000>, <0x0a21b000 0x3000>;
			reg-names = "ccu", "dxe", "pmu";

			memory-region = <&wcnss_mem>;

			interrupts-extended = <&intc GIC_SPI 149 IRQ_TYPE_EDGE_RISING>,
					      <&wcnss_smp2p_in 0 IRQ_TYPE_EDGE_RISING>,
					      <&wcnss_smp2p_in 1 IRQ_TYPE_EDGE_RISING>,
					      <&wcnss_smp2p_in 2 IRQ_TYPE_EDGE_RISING>,
					      <&wcnss_smp2p_in 3 IRQ_TYPE_EDGE_RISING>;
			interrupt-names = "wdog", "fatal", "ready", "handover", "stop-ack";

			power-domains = <&rpmpd MSM8939_VDDCX>,
					<&rpmpd MSM8939_VDDMX_AO>;
			power-domain-names = "vddcx", "vddmx";

			qcom,state = <&wcnss_smp2p_out 0>;
			qcom,state-names = "stop";

			pinctrl-names = "default";
			pinctrl-0 = <&wcnss_pin_a>;

			status = "disabled";

			iris {
				compatible = "qcom,wcn3620";

				clocks = <&rpmcc RPM_SMD_RF_CLK2>;
				clock-names = "xo";
			};

			smd-edge {
				interrupts = <GIC_SPI 142 IRQ_TYPE_EDGE_RISING>;

				qcom,ipc = <&apcs 8 17>;
				qcom,smd-edge = <6>;
				qcom,remote-pid = <4>;

				label = "pronto";

				wcnss_ctrl: wcnss {
					compatible = "qcom,wcnss";
					qcom,smd-channels = "WCNSS_CTRL";

					qcom,mmio = <&pronto>;

					bt {
						compatible = "qcom,wcnss-bt";
					};

					wifi {
						compatible = "qcom,wcnss-wlan";

						interrupts = <GIC_SPI 145 IRQ_TYPE_LEVEL_HIGH>,
							     <GIC_SPI 146 IRQ_TYPE_LEVEL_HIGH>;
						interrupt-names = "tx", "rx";

						qcom,smem-states = <&apps_smsm 10>, <&apps_smsm 9>;
						qcom,smem-state-names = "tx-enable", "tx-rings-empty";
					};
				};
			};
		};

		intc: interrupt-controller@b000000 {
			compatible = "qcom,msm-qgic2";
			interrupt-controller;
			#interrupt-cells = <3>;
			reg = <0x0b000000 0x1000>, <0x0b002000 0x2000>,
			      <0x0b001000 0x1000>, <0x0b004000 0x2000>;
			interrupts = <GIC_PPI 0 (GIC_CPU_MASK_SIMPLE(4) | IRQ_TYPE_LEVEL_HIGH)>;
		};

		apcs_mbox: mailbox@b011000 {
			compatible = "qcom,msm8916-apcs-kpss-global";
			reg = <0x0b011000 0x1000>;
			#mbox-cells = <1>;
			clocks = <&a53pll>, <&gcc GPLL0_VOTE>, <&xo_board>;
			clock-names = "pll", "aux", "ref";
			#clock-cells = <0>;
		};

		apcs: syscon@b011000 {
			compatible = "syscon";
			reg = <0xb011000 0x1000>;
		};

		a53pll: clock@b016000 {
			compatible = "qcom,msm8939-a53pll";
			reg = <0x0b016000 0x40>;
			#clock-cells = <0>;
			clocks = <&xo_board>;
			clock-names = "xo";
			operating-points-v2 = <&a53pllc1_opp_table>;
		};

		apcs0: mailbox@b111000 {
			compatible = "qcom,msm8916-apcs-kpss-global", "syscon";
			reg = <0xb111000 0x1000>;
			#mbox-cells = <1>;
			clocks = <&a53pll_c0>, <&gcc GPLL0_VOTE>, <&xo_board>;
			clock-names = "pll", "aux", "ref";
			#clock-cells = <0>;
		};

		a53pll_c0: clock@b116000 {
			compatible = "qcom,msm8939-a53pll";
			reg = <0xb116000 0x40>;
			#clock-cells = <0>;
			clocks = <&xo_board>;
			clock-names = "xo";
			operating-points-v2 = <&a53pllc0_opp_table>;
		};

		a53pll_cci: clock@b1d0000 {
			compatible = "qcom,msm8939-a53pll";
			reg = <0xb1d0000 0x40>;
			#clock-cells = <0>;
			clocks = <&xo_board>;
			clock-names = "xo";
			operating-points-v2 = <&a53pllcci_opp_table>;
		};

		apcs2: mailbox@b1d1000 {
			compatible = "qcom,msm8916-apcs-kpss-global", "syscon";
			reg = <0xb1d1000 0x1000>;
			#mbox-cells = <1>;
			clocks = <&a53pll_cci>, <&gcc GPLL0_VOTE>, <&xo_board>;
			clock-names = "pll", "aux", "ref";
			#clock-cells = <0>;
		};

		timer@b120000 {
			#address-cells = <1>;
			#size-cells = <1>;
			ranges;
			compatible = "arm,armv7-timer-mem";
			reg = <0x0b120000 0x1000>;
			clock-frequency = <19200000>;

			frame@b121000 {
				frame-number = <0>;
				interrupts = <GIC_SPI 8 IRQ_TYPE_LEVEL_HIGH>,
					     <GIC_SPI 7 IRQ_TYPE_LEVEL_HIGH>;
				reg = <0x0b121000 0x1000>,
				      <0x0b122000 0x1000>;
			};

			frame@b123000 {
				frame-number = <1>;
				interrupts = <GIC_SPI 9 IRQ_TYPE_LEVEL_HIGH>;
				reg = <0x0b123000 0x1000>;
				status = "disabled";
			};

			frame@b124000 {
				frame-number = <2>;
				interrupts = <GIC_SPI 10 IRQ_TYPE_LEVEL_HIGH>;
				reg = <0x0b124000 0x1000>;
				status = "disabled";
			};

			frame@b125000 {
				frame-number = <3>;
				interrupts = <GIC_SPI 11 IRQ_TYPE_LEVEL_HIGH>;
				reg = <0x0b125000 0x1000>;
				status = "disabled";
			};

			frame@b126000 {
				frame-number = <4>;
				interrupts = <GIC_SPI 12 IRQ_TYPE_LEVEL_HIGH>;
				reg = <0x0b126000 0x1000>;
				status = "disabled";
			};

			frame@b127000 {
				frame-number = <5>;
				interrupts = <GIC_SPI 13 IRQ_TYPE_LEVEL_HIGH>;
				reg = <0x0b127000 0x1000>;
				status = "disabled";
			};

			frame@b128000 {
				frame-number = <6>;
				interrupts = <GIC_SPI 14 IRQ_TYPE_LEVEL_HIGH>;
				reg = <0x0b128000 0x1000>;
				status = "disabled";
			};
		};

		cpu0_acc: power-manager@b088000 {
			compatible = "qcom,msm8916-acc";
			reg = <0x0b088000 0x1000>;
			status = "reserved"; /* Controlled by PSCI firmware */
		};

		cpu0_saw: power-manager@b089000 {
			compatible = "qcom,msm8916-saw2-v3.0-cpu", "qcom,saw2";
			reg = <0x0b089000 0x1000>;
			status = "reserved"; /* Controlled by PSCI firmware */
		};

		cpu1_acc: power-manager@b098000 {
			compatible = "qcom,msm8916-acc";
			reg = <0x0b098000 0x1000>;
			status = "reserved"; /* Controlled by PSCI firmware */
		};

		cpu1_saw: power-manager@b099000 {
			compatible = "qcom,msm8916-saw2-v3.0-cpu", "qcom,saw2";
			reg = <0x0b099000 0x1000>;
			status = "reserved"; /* Controlled by PSCI firmware */
		};

		cpu2_acc: power-manager@b0a8000 {
			compatible = "qcom,msm8916-acc";
			reg = <0x0b0a8000 0x1000>;
			status = "reserved"; /* Controlled by PSCI firmware */
		};

		cpu2_saw: power-manager@b0a9000 {
			compatible = "qcom,msm8916-saw2-v3.0-cpu", "qcom,saw2";
			reg = <0x0b0a9000 0x1000>;
			status = "reserved"; /* Controlled by PSCI firmware */
		};

		cpu3_acc: power-manager@b0b8000 {
			compatible = "qcom,msm8916-acc";
			reg = <0x0b0b8000 0x1000>;
			status = "reserved"; /* Controlled by PSCI firmware */
		};

		cpu3_saw: power-manager@b0b9000 {
			compatible = "qcom,msm8916-saw2-v3.0-cpu", "qcom,saw2";
			reg = <0x0b0b9000 0x1000>;
			status = "reserved"; /* Controlled by PSCI firmware */
		};

		cpu4_acc: power-manager@b188000 {
			compatible = "qcom,msm8916-acc";
			reg = <0x0b188000 0x1000>;
			status = "reserved"; /* Controlled by PSCI firmware */
		};

		cpu4_saw: power-manager@b189000 {
			compatible = "qcom,msm8916-saw2-v3.0-cpu", "qcom,saw2";
			reg = <0x0b189000 0x1000>;
			status = "reserved"; /* Controlled by PSCI firmware */
		};

		cpu5_acc: power-manager@b198000 {
			compatible = "qcom,msm8916-acc";
			reg = <0x0b198000 0x1000>;
			status = "reserved"; /* Controlled by PSCI firmware */
		};

		cpu5_saw: power-manager@b199000 {
			compatible = "qcom,msm8916-saw2-v3.0-cpu", "qcom,saw2";
			reg = <0x0b199000 0x1000>;
			status = "reserved"; /* Controlled by PSCI firmware */
		};

		cpu6_acc: power-manager@b1a8000 {
			compatible = "qcom,msm8916-acc";
			reg = <0x0b1a8000 0x1000>;
			status = "reserved"; /* Controlled by PSCI firmware */
		};

		cpu6_saw: power-manager@b1a9000 {
			compatible = "qcom,msm8916-saw2-v3.0-cpu", "qcom,saw2";
			reg = <0x0b1a9000 0x1000>;
			status = "reserved"; /* Controlled by PSCI firmware */
		};

		cpu7_acc: power-manager@b1b8000 {
			compatible = "qcom,msm8916-acc";
			reg = <0x0b1b8000 0x1000>;
			status = "reserved"; /* Controlled by PSCI firmware */
		};

		cpu7_saw: power-manager@b1b9000 {
			compatible = "qcom,msm8916-saw2-v3.0-cpu", "qcom,saw2";
			reg = <0x0b1b9000 0x1000>;
			status = "reserved"; /* Controlled by PSCI firmware */
		};
	};

	thermal-zones {
		cpu0-thermal {
			polling-delay-passive = <250>;
			polling-delay = <1000>;

			thermal-sensors = <&tsens 5>;

			trips {
				cpu0_alert: trip0 {
					temperature = <75000>;
					hysteresis = <2000>;
					type = "passive";
				};

				cpu0_crit: trip1 {
					temperature = <110000>;
					hysteresis = <2000>;
					type = "critical";
				};
			};

			cooling-maps {
				map0 {
					trip = <&cpu0_alert>;
					cooling-device = <&CPU0 THERMAL_NO_LIMIT THERMAL_NO_LIMIT>,
							 <&CPU1 THERMAL_NO_LIMIT THERMAL_NO_LIMIT>,
							 <&CPU2 THERMAL_NO_LIMIT THERMAL_NO_LIMIT>,
							 <&CPU3 THERMAL_NO_LIMIT THERMAL_NO_LIMIT>;
				};
			};
		};

		cpu1-thermal {
			polling-delay-passive = <250>;
			polling-delay = <1000>;

			thermal-sensors = <&tsens 6>;

			trips {
				cpu1_alert: trip0 {
					temperature = <75000>;
					hysteresis = <2000>;
					type = "passive";
				};

				cpu1_crit: trip1 {
					temperature = <110000>;
					hysteresis = <2000>;
					type = "critical";
				};
			};

			cooling-maps {
				map0 {
					trip = <&cpu1_alert>;
					cooling-device = <&CPU0 THERMAL_NO_LIMIT THERMAL_NO_LIMIT>,
							 <&CPU1 THERMAL_NO_LIMIT THERMAL_NO_LIMIT>,
							 <&CPU2 THERMAL_NO_LIMIT THERMAL_NO_LIMIT>,
							 <&CPU3 THERMAL_NO_LIMIT THERMAL_NO_LIMIT>;
				};
			};
		};

		cpu2-thermal {
			polling-delay-passive = <250>;
			polling-delay = <1000>;

			thermal-sensors = <&tsens 7>;

			trips {
				cpu2_alert: trip0 {
					temperature = <75000>;
					hysteresis = <2000>;
					type = "passive";
				};

				cpu2_crit: trip1 {
					temperature = <110000>;
					hysteresis = <2000>;
					type = "critical";
				};
			};

			cooling-maps {
				map0 {
					trip = <&cpu2_alert>;
					cooling-device = <&CPU0 THERMAL_NO_LIMIT THERMAL_NO_LIMIT>,
							 <&CPU1 THERMAL_NO_LIMIT THERMAL_NO_LIMIT>,
							 <&CPU2 THERMAL_NO_LIMIT THERMAL_NO_LIMIT>,
							 <&CPU3 THERMAL_NO_LIMIT THERMAL_NO_LIMIT>;
				};
			};
		};

		cpu3-thermal {
			polling-delay-passive = <250>;
			polling-delay = <1000>;

			thermal-sensors = <&tsens 8>;

			trips {
				cpu3_alert: trip0 {
					temperature = <75000>;
					hysteresis = <2000>;
					type = "passive";
				};

				cpu3_crit: trip1 {
					temperature = <110000>;
					hysteresis = <2000>;
					type = "critical";
				};
			};

			cooling-maps {
				map0 {
					trip = <&cpu3_alert>;
					cooling-device = <&CPU0 THERMAL_NO_LIMIT THERMAL_NO_LIMIT>,
							 <&CPU1 THERMAL_NO_LIMIT THERMAL_NO_LIMIT>,
							 <&CPU2 THERMAL_NO_LIMIT THERMAL_NO_LIMIT>,
							 <&CPU3 THERMAL_NO_LIMIT THERMAL_NO_LIMIT>;
				};
			};
		};

		cpu4567-thermal {
			polling-delay-passive = <250>;
			polling-delay = <1000>;

			thermal-sensors = <&tsens 9>;

			trips {
				cpu4567_alert: trip0 {
					temperature = <75000>;
					hysteresis = <2000>;
					type = "passive";
				};

				cpu4567_crit: trip1 {
					temperature = <110000>;
					hysteresis = <2000>;
					type = "critical";
				};
			};

			cooling-maps {
				map0 {
					trip = <&cpu4567_alert>;
					cooling-device = <&CPU4 THERMAL_NO_LIMIT THERMAL_NO_LIMIT>,
							 <&CPU5 THERMAL_NO_LIMIT THERMAL_NO_LIMIT>,
							 <&CPU6 THERMAL_NO_LIMIT THERMAL_NO_LIMIT>,
							 <&CPU7 THERMAL_NO_LIMIT THERMAL_NO_LIMIT>;
				};
			};
		};

		gpu-thermal {
			polling-delay-passive = <250>;
			polling-delay = <1000>;

			thermal-sensors = <&tsens 3>;

			trips {
				gpu_alert0: trip-point0 {
					temperature = <75000>;
					hysteresis = <2000>;
					type = "passive";
				};

				gpu_crit: gpu_crit {
					temperature = <95000>;
					hysteresis = <2000>;
					type = "critical";
				};
			};
		};
	};


	timer {
		compatible = "arm,armv8-timer";
		interrupts = <GIC_PPI 2 (GIC_CPU_MASK_SIMPLE(4) | IRQ_TYPE_LEVEL_LOW)>,
			     <GIC_PPI 3 (GIC_CPU_MASK_SIMPLE(4) | IRQ_TYPE_LEVEL_LOW)>,
			     <GIC_PPI 4 (GIC_CPU_MASK_SIMPLE(4) | IRQ_TYPE_LEVEL_LOW)>,
			     <GIC_PPI 1 (GIC_CPU_MASK_SIMPLE(4) | IRQ_TYPE_LEVEL_LOW)>;
	};
};
